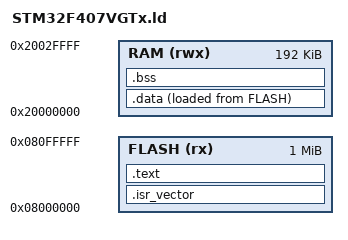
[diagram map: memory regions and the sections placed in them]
ENTRY(Reset_Handler)
_estack = 0x20020000;

MEMORY
{
    FLASH (rx)  : ORIGIN = 0x08000000, LENGTH = 1024K
    RAM   (rwx) : ORIGIN = 0x20000000, LENGTH = 192K
}

SECTIONS
{
    .isr_vector :
    {
        . = ALIGN(4);
        KEEP(*(.isr_vector))
        . = ALIGN(4);
    } > FLASH

    .text :
    {
        . = ALIGN(4);
        *(.text.Reset_Handler)
        *(.text.Default_Handler)
        *(.text)
        *(.text*)
        *(.rodata)
        *(.rodata*)
        . = ALIGN(4);
        _etext = .;
    } > FLASH

    _sidata = LOADADDR(.data);

    .data :
    {
        . = ALIGN(4);
        _sdata = .;
        *(.data)
        *(.data*)
        . = ALIGN(4);
        _edata = .;
    } > RAM AT > FLASH

    .bss (NOLOAD) :
    {
        . = ALIGN(4);
        _sbss = .;
        *(.bss)
        *(.bss*)
        *(COMMON)
        . = ALIGN(4);
        _ebss = .;
    } > RAM
}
